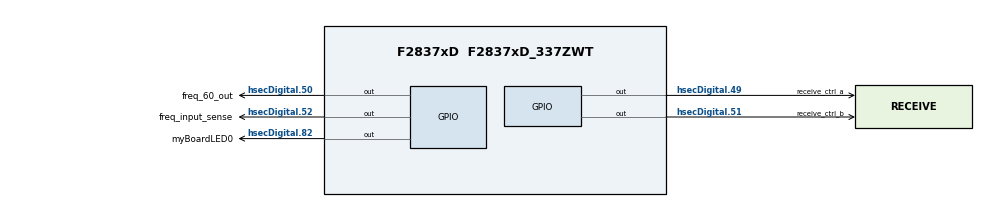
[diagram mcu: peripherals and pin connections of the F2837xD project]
/**
 *
 * @cliArgs --board "/boards/TMDSCNCD28379D" --device "F2837xD" --part "F2837xD_337ZWT" --package "F2837xD_337ZWT" --context "CPU1" --product "C2000WARE@26.01.00.00"
 * @versions {"tool":"1.28.0+4696"}
 */

/**
 * Import the modules used in this configuration.
 */
const led   = scripting.addModule("/driverlib/board_components/led", {}, false);
const led1  = led.addInstance();
const led2  = led.addInstance();
const epwm  = scripting.addModule("/driverlib/epwm.js", {}, false);
const epwm1 = epwm.addInstance();
const epwm2 = epwm.addInstance();
const gpio  = scripting.addModule("/driverlib/gpio.js", {}, false);
const gpio2 = gpio.addInstance();
const gpio4 = gpio.addInstance();
const gpio5 = gpio.addInstance();
const gpio6 = gpio.addInstance();

/**
 * Write custom configuration values to the imported modules.
 */
led1.$name                = "myBoardLED0";
led1.$hardware            = system.deviceData.board.components.D1;
led1.gpio.$name           = "output_ctrl_a";
led1.gpio.gpioPin.$assign = "hsecDigital.82";

led2.$name      = "myBoardLED1";
led2.$hardware  = system.deviceData.board.components.D2;
led2.gpio.$name = "output_ctrl_b";

epwm1.$hardware = system.deviceData.board.components.PWM_LOC2;
epwm1.$name     = "myEPWM2";

epwm2.$hardware = system.deviceData.board.components.PWM_LOC5;
epwm2.$name     = "myEPWM5";

gpio2.$name           = "receive_ctrl_b";
gpio2.gpioPin.$assign = "hsecDigital.51";

gpio4.$name           = "receive_ctrl_a";
gpio4.gpioPin.$assign = "hsecDigital.49";

gpio5.$name           = "freq_60_out";
gpio5.direction       = "GPIO_DIR_MODE_OUT";
gpio5.gpioPin.$assign = "hsecDigital.50";

gpio6.$name           = "freq_input_sense";
gpio6.gpioPin.$assign = "hsecDigital.52";

/**
 * Pinmux solution for unlocked pins/peripherals. This ensures that minor changes to the automatic solver in a future
 * version of the tool will not impact the pinmux you originally saw.  These lines can be completely deleted in order to
 * re-solve from scratch.
 */
led2.gpio.gpioPin.$suggestSolution    = "hsecDigital.86";
epwm1.epwm.$suggestSolution           = "EPWM2";
epwm1.epwm.epwm_aPin.$suggestSolution = "hsecDigital.53";
epwm1.epwm.epwm_bPin.$suggestSolution = "hsecDigital.55";
epwm2.epwm.$suggestSolution           = "EPWM5";
epwm2.epwm.epwm_aPin.$suggestSolution = "hsecDigital.57";
epwm2.epwm.epwm_bPin.$suggestSolution = "hsecDigital.59";
